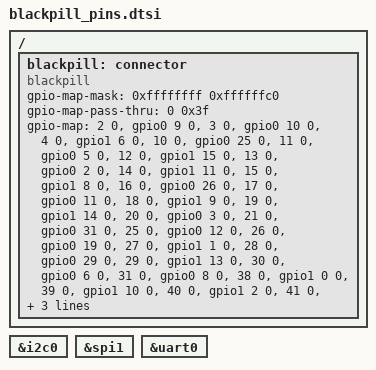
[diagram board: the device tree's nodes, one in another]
/*
 * Copyright (c) 2022 Kyle McCreery
 *
 * SPDX-License-Identifier: MIT
 */

/ {
    blackpill: connector {
        compatible = "blackpill";
        #gpio-cells = <2>;
        gpio-map-mask = <0xffffffff 0xffffffc0>;
        gpio-map-pass-thru = <0 0x3f>;
        gpio-map
            = <2  0 &gpio0 9  0>    /* PC13 */
            , <3  0 &gpio0 10 0>    /* PC14 */
            , <4  0 &gpio1 6  0>    /* PC15 */
            , <10 0 &gpio0 25 0>    /* PA0  */
            , <11 0 &gpio0 5  0>    /* PA1  */
            , <12 0 &gpio1 15 0>    /* PA2  */
            , <13 0 &gpio0 2  0>    /* PA3  */
            , <14 0 &gpio1 11 0>    /* PA4  */
            , <15 0 &gpio1 8  0>    /* PA5  */
            , <16 0 &gpio0 26 0>    /* PA6  */
            , <17 0 &gpio0 11 0>    /* PA7  */
            , <18 0 &gpio1 9  0>    /* PB0  */
            , <19 0 &gpio1 14 0>    /* PB1  */
            , <20 0 &gpio0 3  0>    /* PB2  */
            , <21 0 &gpio0 31 0>    /* PB10 */
            , <25 0 &gpio0 12 0>    /* PB12 */
            , <26 0 &gpio0 19 0>    /* PB13 */
            , <27 0 &gpio1 1  0>    /* PB14 */
            , <28 0 &gpio0 29 0>    /* PB15 */
            , <29 0 &gpio1 13 0>    /* PA8  */
            , <30 0 &gpio0 6  0>    /* PA9  */
            , <31 0 &gpio0 8  0>    /* PA10 */
            , <38 0 &gpio1 0  0>    /* PA15 */
            , <39 0 &gpio1 10 0>    /* PB3  */
            , <40 0 &gpio1 2  0>    /* PB4  */
            , <41 0 &gpio1 4  0>    /* PB5  */
            , <42 0 &gpio0 13 0>    /* PB6  */
            , <43 0 &gpio0 15 0>    /* PB7  */
            , <45 0 &gpio0 17 0>    /* PB8  */
            , <46 0 &gpio0 24 0>    /* PB9  */
            ;
    };
};

blackpill_i2c: &i2c0 {};
blackpill_spi: &spi1 {};
blackpill_serial: &uart0 {};
